# R40 register map
Vendor: Allwinner; Series: R40; File version: 0.1
CPU: CA7 0, little endian, MPU, FPU, double-precision FPU, 0 interrupt priority bits
Registers are 32-bit, read-write, reset 0x0 unless marked. A register's access mark holds for its fields unless they carry their own. Offsets are from the block's base; [hi:lo] are bit positions; {n}, {i} and the like mark numbered series; 'fields as' and 'values as' point back to an identical list.

## NDFC
Base 0x01C03000
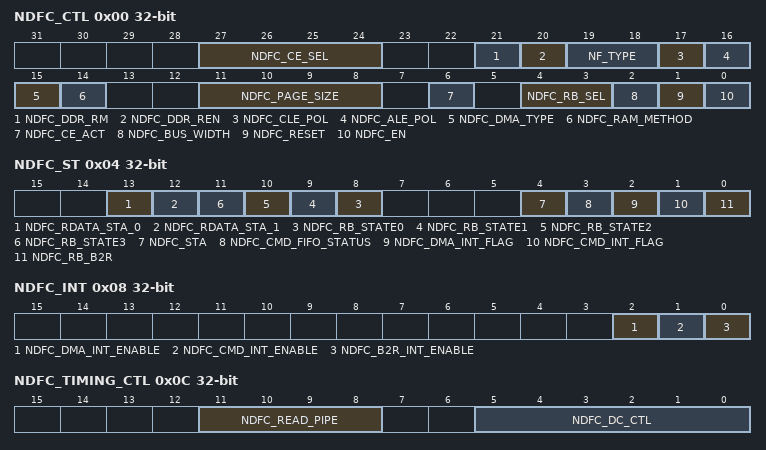
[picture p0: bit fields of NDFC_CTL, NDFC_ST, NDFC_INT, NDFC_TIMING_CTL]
0x00 NDFC_CTL — NDFC Configure and Control Register
  [27:24] NDFC_CE_SEL — Chip Select for 8 NAND Flash Chips 0000 ~ 0111: NDFC Chip Select Signal 0-7 is selected 1000 ~ 1111: NDFC CS[7:0] is not selected. GPIO pins can be used for CS.
  [21] NDFC_DDR_RM — DDR Repeat Data Mode 0: Lower byte 1: Higher byte
    0=Lower byte; 1=Higher byte
  [20] NDFC_DDR_REN — DDR Repeat Enable 0: Disable 1: Enable
    0=Disable; 1=Enable
  [19:18] NF_TYPE — NAND Flash Type 00: Normal SDR NAND 01: Reserved 10: ONFI DDR NAND 11: Toggle DDR NAND
    0=Normal SDR NAND; 2=ONFI (ONFI DDR NAND); 3=Toggle DDR NAND
  [17] NDFC_CLE_POL — NDFC Command Latch Enable (CLE) Signal Polarity Select 0: High active 1: Low active
    0=High active; 1=Low (Low active)
  [16] NDFC_ALE_POL — NDFC Address Latch Enable (ALE) Signal Polarity Select 0: High active 1: Low active
    0=High active; 1=Low (Low active)
  [15] NDFC_DMA_TYPE — 0: Dedicated DMA 1: Normal DMA
    0=Dedicated DMA; 1=Normal DMA
  [14] NDFC_RAM_METHOD — Access Internal RAM Method 0: Access internal RAM by AHB bus 1: Access internal RAM by DMA bus
    0=Access internal RAM by AHB bus; 1=Access internal RAM by DMA bus
  [11:8] NDFC_PAGE_SIZE — 0000: 1024 bytes 0001: 2048 bytes 0010: 4096 bytes 0011: 8192 bytes 0100: 16384 bytes The page size is for main field data.
    0=1024 bytes; 1=2048 bytes; 2=4096 bytes; 3=8192 bytes; 4=16384 bytes The page size is for main field data
  [6] NDFC_CE_ACT — Chip Select Signal CE# Control during NAND Operation 0: De-active Chip Select Signal NDFC_CE# during data loading, serial access and other no operation stage for power consumption. NDFC automatic control Chip Select Signals. 1: Chip select signal NDFC_CE# is always active after NDFC is enabled.
    0=De-active Chip Select Signal NDFC_CE# during data loading, serial access and other no operation stage for power consumption. NDFC automatic control Chip Select Signals.; 1=Chip select signal NDFC_CE# is always active after NDFC is enabled
  [4:3] NDFC_RB_SEL — NDFC external R/B Signal select The value 0-3 selects the external R/B signal. The same R/B signal can be used for multiple chip select flash.
  [2] NDFC_BUS_WIDTH — 0: 8-bit bus 1: 16-bit bus
    0=8-bit bus; 1=16-bit bus
  [1] NDFC_RESET — NDFC Reset Write 1 to reset NDFC and clear to 0 after reset
  [0] NDFC_EN — NDFC Enable Control 0: Disable NDFC 1: Enable NDFC
    0=Disable NDFC; 1=Enable NDFC
0x04 NDFC_ST — NDFC Status Information Register
  [13] NDFC_RDATA_STA_0 ro — 0: The number of bit 1 during current read operation is greater threshold value. 1: The number of bit 1 during current read operation is less than or equal to threshold value. This field only is valid when is 1. The threshold value is configured in .
    0=greater (The number of bit 1 during current read operation is greater threshold value.); 1=less (The number of bit 1 during current read operation is less than or equal to threshold value. This field only is valid when is 1. The threshold value is configured in .)
  [12] NDFC_RDATA_STA_1 ro — 0: The number of bit 0 during current read operation is greater threshold value. 1: The number of bit 0 during current read operation is less than or equal to than threshold value. This field only is valid when is 1. The threshold value is configured in .
    0=greater (The number of bit 0 during current read operation is greater threshold value.); 1=less (The number of bit 0 during current read operation is less than or equal to than threshold value. This field only is valid when is 1. The threshold value is configured in .)
  [n+8] NDFC_RB_STATE{n} ro (n=0..3) — NAND Flash R/B {n} Line State 0: NAND Flash in BUSY State 1: NAND Flash in READY State
    0=NAND Flash in BUSY State; 1=NAND Flash in READY State
  [4] NDFC_STA ro — 0: NDFC FSM in IDLE State 1: NDFC FSM in BUSY State When NDFC_STA is 0, NDFC can accept new command and process command.
    0=NDFC FSM in IDLE State; 1=NDFC FSM in BUSY State When NDFC_STA is 0, NDFC can accept new command and process command
  [3] NDFC_CMD_FIFO_STATUS ro — 0: Command FIFO not full and can receive new command 1: Full and waiting NDFC to process commands in FIFO Since there is only one 32-bit FIFO for command. When NDFC latches one command, command FIFO is free and can accept another new command.
    0=Command FIFO not full and can receive new command; 1=Full and waiting NDFC to process commands in FIFO Since there is only one 32-bit FIFO for command. When NDFC latches one command, command FIFO is free and can accept another new command.
  [2] NDFC_DMA_INT_FLAG — When it is 1, it means that a pending DMA is completed. It will be cleared after writing 1 to this bit or it will be automatically cleared before FSM processing an new command.
  [1] NDFC_CMD_INT_FLAG — When it is 1, it means that NDFC has finished one Normal Command Mode or one Batch Command Work Mode. It will be cleared after writing 1 to this bit or it will be automatically cleared before FSM processing a new command.
  [0] NDFC_RB_B2R — When it is 1, it means that NDFC_R/B# signal is transferred from BUSY state to READY state. It will be cleared after writing 1 to this bit.
0x08 NDFC_INT — NDFC Interrupt Control Register
  [2] NDFC_DMA_INT_ENABLE — Enable or disable interrupt when a pending DMA is completed.
  [1] NDFC_CMD_INT_ENABLE — Enable or disable interrupt when NDFC has finished the procession of a single command in Normal Command Work Mode or one Batch Command Work Mode. 0: Disable 1: Enable
    0=Disable; 1=Enable
  [0] NDFC_B2R_INT_ENABLE — Enable or disable interrupt when NDFC_RB# signal is transferring from BUSY state to READY state. 0: Disable 1: Enable
    0=Disable; 1=Enable
0x0C NDFC_TIMING_CTL — NDFC Timing Control Register
  [11:8] NDFC_READ_PIPE — In SDR mode: 0000: Normal 0001: EDO 0010: E-EDO Other : Reserved In DDR mode: 0001~1111 is valid.(These bits configure the number of clock when data is valid after RE#`s falling edge)
    0=Normal; 1=EDO; 2=E_minus_EDO_Other (E-EDO Other : Reserved In DDR mode: 0001~1111 is valid.(These bits configure the number of clock when data is valid after RE#`s falling edge))
  [5:0] NDFC_DC_CTL — NDFC Delay Chain Control. (These bits are only valid in DDR data interface, and configure the relative phase between DQS and DQ*0...7+)
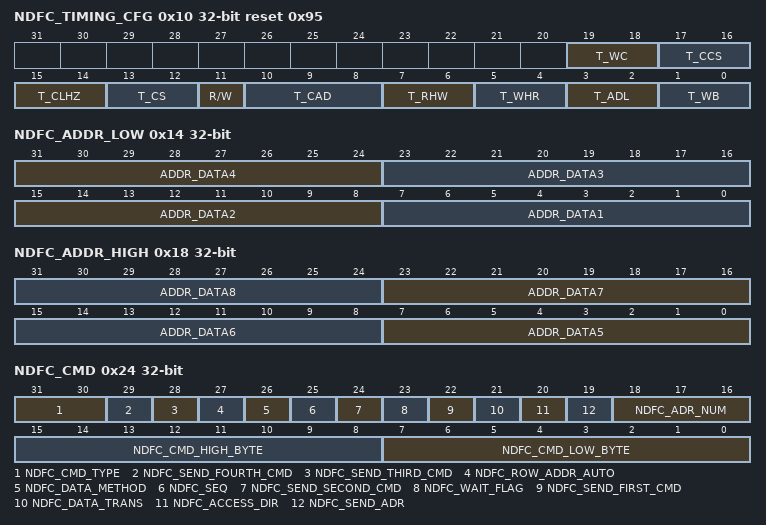
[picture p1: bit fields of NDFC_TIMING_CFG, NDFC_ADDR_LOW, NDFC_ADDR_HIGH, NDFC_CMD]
0x10 NDFC_TIMING_CFG reset 0x95 — NDFC Timing Configure Register
  [19:18] T_WC — Write Cycle Time 00: 1*2T 01: 2*2T 10: 3*2T 11: 4*2T
    {v}=_{v+1}_times_2T ({v+1}*2T) (v=0..3)
  [17:16] T_CCS — Change Column Setup Time 00: 16*2T 01: 24*2T 10: 32*2T 11: 64*2T
    0=_16_times_2T (16*2T); 1=_24_times_2T (24*2T); 2=_32_times_2T (32*2T); 3=_64_times_2T (64*2T)
  [15:14] T_CLHZ — CLE High to Output Hi-z 00: 2*2T 01: 8*2T 10: 16*2T 11: 31*2T
    0=_2_times_2T (2*2T); 1=_8_times_2T (8*2T); 2=_16_times_2T (16*2T); 3=_31_times_2T (31*2T)
  [13:12] T_CS — CE Setup Time 00: 2*2T 01: 8*2T 10: 16*2T 11: 31*2T
    values as T_CLHZ
  [11] R/W — 0x0 T_CDQSS DQS Setup Time for Data Input Start 0: 8*2T 1: 24*2T
    0=_8_times_2T (8*2T); 1=_24_times_2T (24*2T)
  [10:8] T_CAD — Command, Address, Data Delay 000: 4*2T 001: 8*2T 010: 12*2T 011: 16*2T 100: 24*2T 101: 32*2T 110/111: 64*2T
    0=_4_times_2T (4*2T); 1=_8_times_2T (8*2T); 2=_12_times_2T (12*2T); 3=_16_times_2T (16*2T); 4=_24_times_2T (24*2T); 5=_32_times_2T (32*2T 110/111: 64*2T)
  [7:6] T_RHW — RE# High to WE# Low Cycle Number 00: 4*2T 01: 8*2T 10: 12*2T 11: 20*2T
    0=_4_times_2T (4*2T); 1=_8_times_2T (8*2T); 2=_12_times_2T (12*2T); 3=_20_times_2T (20*2T)
  [5:4] T_WHR — WE# High to RE# Low Cycle Number 00: 8*2T 01: 16*2T 10: 24*2T 11: 32*2T
    0=_8_times_2T (8*2T); 1=_16_times_2T (16*2T); 2=_24_times_2T (24*2T); 3=_32_times_2T (32*2T)
  [3:2] T_ADL — Address to Data Loading Cycle Number 00: 0*2T 01: 8*2T 10: 16*2T 11: 24*2T
    0=_0_times_2T (0*2T); 1=_8_times_2T (8*2T); 2=_16_times_2T (16*2T); 3=_24_times_2T (24*2T)
  [1:0] T_WB — WE# High to Busy Cycle Number 00: 14*2T 01: 22*2T 10: 30*2T 11: 38*2T
    0=_14_times_2T (14*2T); 1=_22_times_2T (22*2T); 2=_30_times_2T (30*2T); 3=_38_times_2T (38*2T)
0x14 NDFC_ADDR_LOW — NDFC Low Word Address Register
  [31:24] ADDR_DATA4 — NAND Flash 4th Cycle Address Data
  [23:16] ADDR_DATA3 — NAND Flash 3rd Cycle Address Data
  [15:8] ADDR_DATA2 — NAND Flash 2nd Cycle Address Data
  [7:0] ADDR_DATA1 — NAND Flash 1st Cycle Address Data
0x18 NDFC_ADDR_HIGH — NDFC High Word Address Register
  [8n-33:8n-40] ADDR_DATA{n} (n=5..8) — NAND Flash {n}th Cycle Address Data
0x1C NDFC_DATA_BLOCK_NUM
  [4:0] DATA_BLOCK_NUM — DATA BLOCK Number It is used for batch command procession. 00000: no data 00001: 1 data block 00010: 2 data blocks ... 10000: 16 data blocks Others: Reserved Note: 1 data block = 512 or 1024 bytes main field data
    0=no_data; 1=1 data block; 2=2 data blocks ; 16=16 data blocks Others: Reserved Note: 1 data block = 512 or 1024 bytes main field data
0x20 NDFC_CNT — NDFC Data Counter for Data Transfer Register
  [9:0] NDFC_DATA_CNT — Transfer Data Byte Counter The length can be set from 1 byte to 1024 bytes. However, 1024 bytes is set when it is zero.
0x24 NDFC_CMD — Set up NDFC Commands Register
  [31:30] NDFC_CMD_TYPE — 00: Common Command for normal operation 01: Special Command for Flash Spare Field Operation 10: Page Command for batch process operation 11: Reserved
    0=Common Command for normal operation; 1=Special Command for Flash Spare Field Operation; 2=Page Command for batch process operation
  [29] NDFC_SEND_FOURTH_CMD — 0: Don`t send third set command 1: Send it on the external memory`s bus It is used for EF-NAND page read.
    0=Don`t send third set command; 1=Send it on the external memory`s bus It is used for EF-NAND page read
  [28] NDFC_SEND_THIRD_CMD — 0: Don`t send third set command 1: Send it on the external memory`s bus It is used for EF-NAND page read.
    values as NDFC_SEND_FOURTH_CMD
  [27] NDFC_ROW_ADDR_AUTO — Row Address Auto Increase for Page Command 0: Normal operation 1: Row address increasing automatically
    0=Normal operation; 1=Row (Row address increasing automatically)
  [26] NDFC_DATA_METHOD — Data swap method when the internal RAM and system memory It is only active for Common Command and Special Command. 0: No action 1: DMA transfer automatically It only is active when is 1. If this bit is set to 1, NDFC should setup DRQ to fetching data before output to Flash or NDFC should setup DRQ to sending out to system memory after fetching data from Flash. If this bit is set to 0, NDFC output the data in internal RAM or do nothing after fetching data from Flash.
    0=No_action; 1=DMA (DMA transfer automatically It only is active when is 1. If this bit is set to 1, NDFC should setup DRQ to fetching data before output to Flash or NDFC should setup DRQ to sending out to system memory after fetching data from Flash. If this bit is set to 0, NDFC output the data in internal RAM or do nothing after fetching data from Flash.)
  [25] NDFC_SEQ — User data & BCH check word position. It only is active for Page Command, don`t care about this bit for other two commands 0: Interleave Method (on page spare area) 1: Sequence Method (following data block)
    0=Interleave Method (on page spare area); 1=Sequence Method (following data block)
  [24] NDFC_SEND_SECOND_CMD — 0: Don`t send second set command 1: Send it on the external memory`s bus
    0=Don`t send second set command; 1=Send it on the external memory`s bus
  [23] NDFC_WAIT_FLAG — 0: NDFC can transfer data regardless of the internal NDFC_RB wire 1: NDFC can transfer data when the internal NDFC_RB wire is READY; otherwise it can`t when the internal NDFC_RB wire is BUSY.
    0=NDFC can transfer data regardless of the internal NDFC_RB wire; 1=NDFC can transfer data when the internal NDFC_RB wire is READY; otherwise it can`t when the internal NDFC_RB wire is BUSY
  [22] NDFC_SEND_FIRST_CMD — 0: Don`t send first set command 1: Send it on the external memory`s bus
    0=Don`t send first set command; 1=Send it on the external memory`s bus
  [21] NDFC_DATA_TRANS — 0: No data transfer on external memory bus 1: Data transfer and direction is decided by the field
    0=No data transfer on external memory bus; 1=Data transfer and direction is decided by the field
  [20] NDFC_ACCESS_DIR — 0: Read NAND Flash 1: Write NAND Flash
    0=Read NAND Flash; 1=Write NAND Flash
  [19] NDFC_SEND_ADR — 0: Don`t send ADDRESS 1: Send N cycles ADDRESS, the number N is specified by
    0=Don`t send ADDRESS; 1=Send N cycles ADDRESS, the number N is specified by
  [18:16] NDFC_ADR_NUM — Address Cycles` Number 000: 1 cycle address field 001: 2 cycles address field 010: 3 cycles address field 011: 4 cycles address field 100: 5 cycles address field 101: 6 cycles address field 110: 7 cycles address field 111: 8 cycles address field
    0=1 cycle address field; {v}={v+1} cycles address field (v=1..7)
  [15:8] NDFC_CMD_HIGH_BYTE — NDFC Command high byte data If 8-bit command is supported, the high byte should be zero for 16-bit bus width NAND Flash. For 8-bit bus width NAND Flash, high byte command is discarded.
  [7:0] NDFC_CMD_LOW_BYTE — NDFC Command low byte data This command will be sent to external Flash by NDFC.
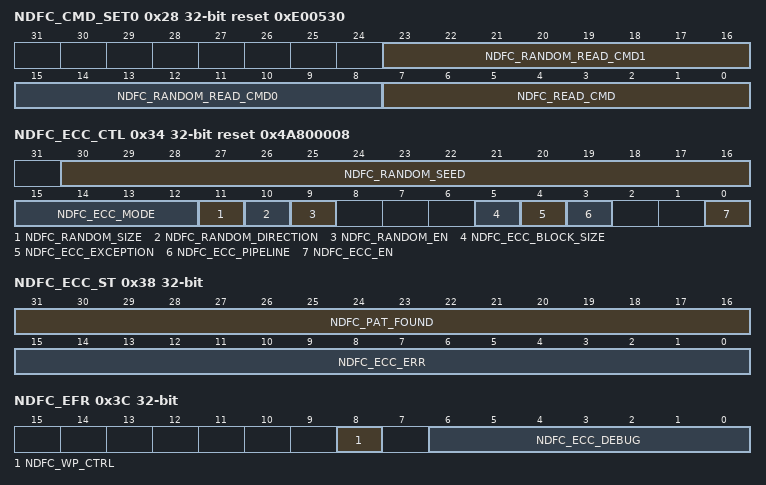
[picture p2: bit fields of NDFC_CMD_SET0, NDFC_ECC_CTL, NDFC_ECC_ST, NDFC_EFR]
0x28 NDFC_CMD_SET0 reset 0xE00530
  [23:16] NDFC_RANDOM_READ_CMD1 — Used for Batch Read Operation
  [15:8] NDFC_RANDOM_READ_CMD0 — Used for Batch Read Operation
  [7:0] NDFC_READ_CMD — Used for Batch Read Operation
0x2C NDFC_CMD_SET1 reset 0x708510
  [31:16] NDFC_READ_CMD0 — Used for EF-NAND Page Read Operation
  [23:16] NDFC_READ_CMD1 — Used for EF-NAND Page Read Operation
  [15:8] NDFC_RANDOM_WRITE_CMD — Used for Batch Write Operation
  [7:0] NDFC_PROGRAM_CMD — Used for Batch Write Operation
0x34 NDFC_ECC_CTL reset 0x4A800008 — ECC Configure and Control Register
  [30:16] NDFC_RANDOM_SEED — The seed value for randomize engine. It is only active when is set to `1`.
  [15:12] NDFC_ECC_MODE — 0000: BCH-16 for one ECC Data Block 0001: BCH-24 for one ECC Data Block 0010 : BCH-28 for one ECC Data Block 0011 : BCH-32 for one ECC Data Block 0100 : BCH-40 for one ECC Data Block 0101 : BCH-48 for one ECC Data Block 0110 : BCH-56 for one ECC Data Block 0111 : BCH-60 for one ECC Data Block 1000 : BCH-64 for one ECC Data Block Others: Reserved
    0=BCH_minus_16 (BCH-16 for one ECC Data Block); 1=BCH_minus_24 (BCH-24 for one ECC Data Block 0010 : BCH-28 for one ECC Data Block 0011 : BCH-32 for one ECC Data Block 0100 : BCH-40 for one ECC Data Block 0101 : BCH-48 for one ECC Data Block 0110 : BCH-56 for one ECC Data Block 0111 : BCH-60 for one ECC Data Block 1000 : BCH-64 for one ECC Data Block Others: Reserved)
  [11] NDFC_RANDOM_SIZE — 0: ECC block size 1: Page size
    0=ECC (ECC block size); 1=Page size
  [10] NDFC_RANDOM_DIRECTION — 0: LSB first 1: MSB first
    0=LSB (LSB first); 1=MSB (MSB first)
  [9] NDFC_RANDOM_EN — 0: Disable Data Randomize 1: Enable Data Randomize
    0=Disable Data Randomize; 1=Enable Data Randomize
  [5] NDFC_ECC_BLOCK_SIZE — 0: 1024 bytes of one ECC data block 1: 512 bytes of one ECC data block
    0=1024 bytes of one ECC data block; 1=512 bytes of one ECC data block
  [4] NDFC_ECC_EXCEPTION — 0: Normal ECC 1: For ECC, there is an exception. If all data is 0xff or 0x00 for the block. When reading this page, ECC assumes that it is right. For this case, no error information is reported. Note: It is only active when ECC is ON
    0=Normal ECC; 1=For (For ECC, there is an exception. If all data is 0xff or 0x00 for the block. When reading this page, ECC assumes that it is right. For this case, no error information is reported. Note: It is only active when ECC is ON)
  [3] NDFC_ECC_PIPELINE — Pipeline function enable or disable for batch command 0: Error Correction function no pipeline with next block operation 1: Error Correction pipeline
    0=Error Correction function no pipeline with next block operation; 1=Error_Correction_pipeline
  [0] NDFC_ECC_EN — 0: ECC is OFF 1: ECC is ON
    0=OFF (ECC is OFF); 1=ON (ECC is ON)
0x38 NDFC_ECC_ST — ECC Status and Operation Information Register
  [31:16] NDFC_PAT_FOUND ro — Special pattern (all 0x00 or all x0ff) Found Flag for 16 Data Blocks 0: No Found 1: Special pattern is found When this field is `1`, this means that the special data is found for reading external NAND flash. The register of would indicate which pattern is found.
  [15:0] NDFC_ECC_ERR ro — Error information bit of 16 Data Blocks 0: ECC can correct these error bits or there is no error bit 1: Error bits number beyond of ECC correction capability and can not correct them Note: The LSB of this register is corresponding the 1st ECC data block. 1 ECC Data Block = 512 or 1024 byte.
0x3C NDFC_EFR — Enhanced Feature Register
  [8] NDFC_WP_CTRL — NAND Flash Write Protect Control 0: Write Protect is active 1: Write Protect is not active When the bit is `0`, WP signal line is low level and external NAND flash is on protected state.
    0=active (Write Protect is active); 1=not_active (Write Protect is not active When the bit is `0`, WP signal line is low level and external NAND flash is on protected state.)
  [6:0] NDFC_ECC_DEBUG — For the purpose of debugging ECC engine, special bit error is inserted before writing external Flash Memory. 0: No error is inserted (ECC Normal Operation) n: N bits error are inserted
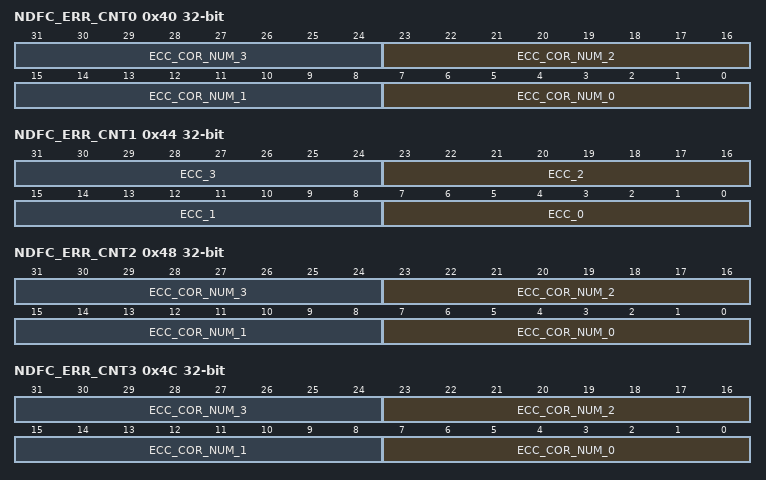
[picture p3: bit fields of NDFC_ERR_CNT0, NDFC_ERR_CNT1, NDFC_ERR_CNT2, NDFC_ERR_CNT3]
0x40 NDFC_ERR_CNT0 — Corrected Error Bit Counter Register 0
  [8n+7:8n] ECC_COR_NUM_{n} ro (n=0..3) — ECC Corrected Bits Number for ECC Data Block[n] (n from 0 to 3) 0: No corrected bit 1: 1 corrected bit 2: 2 corrected bit ... 64: 64 corrected bit Others: Reserved Note: 1 ECC Data Block = 512 or 1024 byte
0x44 NDFC_ERR_CNT1 — Corrected Error Bit Counter Register 1
  [8n+7:8n] ECC_{n} ro (n=0..3) — ECC_COR_NUM ECC Corrected Bits Number for ECC Data Block[n] (n from 4 to 7) 0000000: No corrected bit 0000001: 1 corrected bit 0000010: 2 corrected bit ... 1000000: 64 corrected bit Others: Reserved Note: 1 ECC Data Block = 512 or 1024 byte
0x48 NDFC_ERR_CNT2
  [8n+7:8n] ECC_COR_NUM_{n} ro (n=0..3) — ECC Corrected Bits Number for ECC Data Block[n] (n from 8 to 11) 0000000: No corrected bit 0000001: 1 corrected bit 0000010: 2 corrected bit ... 1000000: 64 corrected bit Others: Reserved Note: 1 ECC Data Block = 512 or 1024 byte
0x4C NDFC_ERR_CNT3
  [8n+7:8n] ECC_COR_NUM_{n} ro (n=0..3) — ECC Corrected Bits Number for ECC Data Block[n] (n from 12 to 15) 0000000: No corrected bit 0000001: 1 corrected bit 0000010: 2 corrected bit ... 1000000: 64 corrected bit Others: Reserved Note: 1 ECC Data Block = 512 or 1024 byte
{0x50+4i} NDFC_USER_DATAn[{i}] (i=0..15) reset 0xFFFFFFFF — User Data Field Register N (N from 0 to 15)
  [31:0] USER_DATA — User Data for ECC Data Block[n] (n from 0 to 15) Note: 1 ECC Data Block = 512 or 1024 bytes
0x90 NDFC_EFNAND_STATUS
  [7:0] EF_NAND_STATUS ro — The Status Value for EF-NAND Page Read operation
0xA0 NDFC_SPARE_AREA reset 0x400 — Spare Area Configure Register
  [15:0] NDFC_SPARE_ADR — This value indicates the spare area first byte address for NDFC interleave page operation.
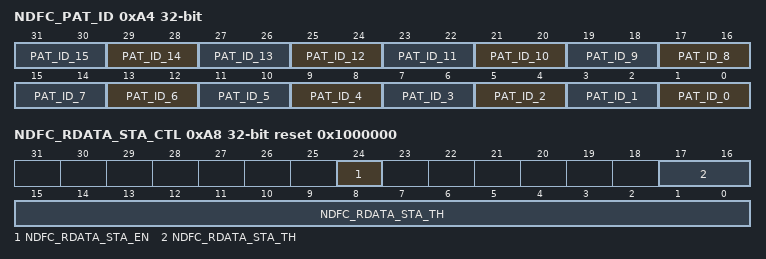
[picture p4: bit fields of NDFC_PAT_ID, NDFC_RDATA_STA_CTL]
0xA4 NDFC_PAT_ID — Pattern ID Register
  [2n+1:2n] PAT_ID_{n} ro (n=0..15) — Special Pattern ID for 16 ECC data block 0: All 0x00 is found 1: All 0xFF is found Others: Reserved
0xA8 NDFC_RDATA_STA_CTL reset 0x1000000 — Read Data Status Control Register
  [24] NDFC_RDATA_STA_EN — 0: Disable to count the number of bit 1 and bit 0 during current read operation 1: Enable to count the number of bit 1 and bit 0 during current read operation The number of bit 1 and bit 0 during current read operation can be used to check whether a page is blank or bad.
    0=Disable to count the number of bit 1 and bit 0 during current read operation; 1=Enable to count the number of bit 1 and bit 0 during current read operation The number of bit 1 and bit 0 during current read operation can be used to check whether a page is blank or bad
  [17:0] NDFC_RDATA_STA_TH — The threshold value to generate data status. If the number of bit 1 during current read operation is less than or equal to threshold value, will be set. If the number of bit 0 during current read operation is less than or equal to threshold value, will be set.
0xAC NDFC_RDATA_STA_0 — Read Data Status Register 0
  [31:0] BIT_CNT_1 ro — The number of input bit 1 during current command. It will be cleared automatically when next command is executed.
0xB0 NDFC_RDATA_STA_1 — Read Data Status Register 1
  [31:0] BIT_CNT_0 ro — The number of input bit 0 during current command. It will be cleared automatically when next command is executed.
0xC0 NDFC_MDMA_ADDR — MBUS DMA Address Register
  [31:0] MDMA_ADDR — MBUS DMA address
0xC4 NDFC_MDMA_CNT — MBUS DMA Data Counter Register
  [14:0] MDMA_CNT — MBUS DMA data counter
0xD0 NDFC_NDMA_MODE_CTL reset 0xA5 — NDFC Normal DMA Mode Control Register
  [7:0] NDMA_MODE_CTL — 0xEA:NDMA handshake mode Note: NDMA wait mode don't care this value. 0xA5 can be used in handshake mode, but 0xEA is better.
0x300 NDFC_IO_DATA — Data Input/Output Port Address Register
  [31:0] NDFC_IO_DATA — Read/Write data into internal RAM Access unit is 32-bit.
